# CY8C5568AXI_060 register map
File version: 0.1
CY8C55
Registers are 8-bit, read-write, no defined reset value unless marked. A register's access mark holds for its fields unless they carry their own. Offsets are from the block's base; lines under a group give offsets from that group; [hi:lo] are bit positions; {n}, {i} and the like mark numbered series; 'fields as' and 'values as' point back to an identical list; <NAME> marks a mode.

## Memory map
0x400049C8 I2C_1 size 0x14

## I2C_1
Base 0x400049C8
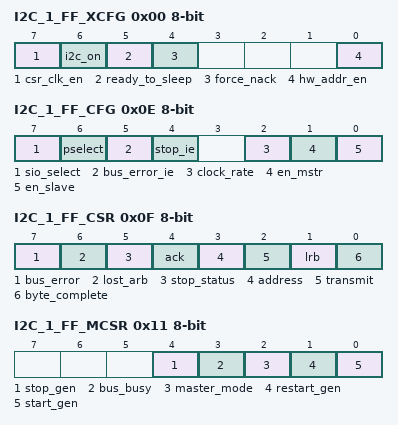
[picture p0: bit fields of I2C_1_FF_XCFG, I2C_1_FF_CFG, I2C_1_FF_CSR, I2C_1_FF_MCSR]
0x00 I2C_1_FF_XCFG — Extended Configuration Register: I2C_XCFG
  [7] csr_clk_en, [6] i2c_on, [5] ready_to_sleep ro, [4] force_nack, [0] hw_addr_en
0x02 I2C_1_FF_ADDR — Slave Adddress Register: I2C_ADR
  [6:0] slave_address — This register holds the slave's 7-bit address.
0x0E I2C_1_FF_CFG — Configuration Register: I2C_CFG
  [7] sio_select, [6] pselect, [5] bus_error_ie, [4] stop_ie, [2] clock_rate, [1] en_mstr, [0] en_slave
0x0F I2C_1_FF_CSR — Control and Status Register: I2C_CSR
  [7] bus_error, [6] lost_arb, [5] stop_status, [4] ack, [3] address, [2] transmit, [1] lrb, [0] byte_complete
0x10 I2C_1_FF_DATA — Data Register: I2C_D
  [7:0] data — This register provides read/write access to the Shift register.
0x11 I2C_1_FF_MCSR — Master Control and Status Register: I2C_MCSR
  [4] stop_gen, [3] bus_busy ro, [2] master_mode ro, [1] restart_gen, [0] start_gen
0x13 I2C_1_FF__CLK_DIV — Divider of BUS_CLK presented power of 2: I2C_CLK_DIV
  [2:0] Div
